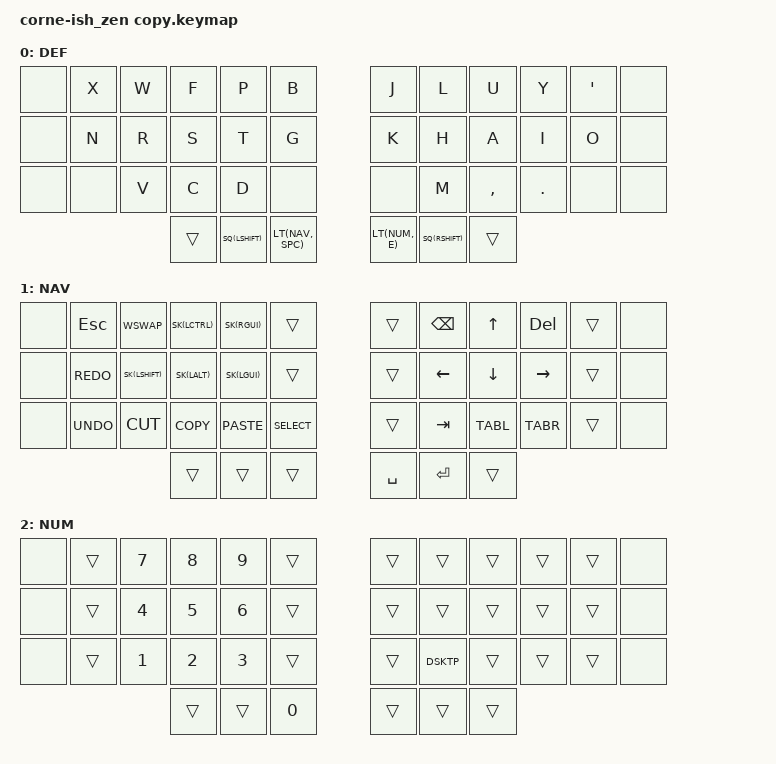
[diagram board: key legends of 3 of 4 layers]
#include <behaviors.dtsi>
#include <dt-bindings/zmk/keys.h>
#include <dt-bindings/zmk/bt.h>

// Keep sticky keys active for a long time so they effectively do not time out
#define STICKY_KEY_TIMEOUT 60000

#define XXXXX &none
#define _____ &trans

#define DEF 0
#define NAV 1
#define NUM 2

#define SK(KEY) &nk KEY KEY
#define MR(LAYER) &mr LAYER 0
#define SQ(KEY) &skq KEY
#define LT(LAYER, KEY) &lt LAYER KEY

#define WSWAP LG(NON_US_BACKSLASH)
#define win_next LS(LG(NON_US_BACKSLASH))
#define TABL LS(LG(LEFT_BRACKET))
#define TABR LS(LG(RIGHT_BRACKET))

#define UNDO LG(Z)
#define REDO LS(LG(Z))
#define COPY LG(C)
#define PASTE LG(V)
#define CUT LG(X)
#define SELECT LG(A)

// #define DSKT1 &kp LS(LC(LA(LG(N1))))
// #define DSKT2 &kp LS(LC(LA(LG(N2))))
// #define DSKT3 &kp LS(LC(LA(LG(N3))))
// #define DSKT4 &kp LS(LC(LA(LG(N4))))
// #define DSKT5 &kp LS(LC(LA(LG(N5))))
// #define DSKT6 &kp LS(LC(LA(LG(N6))))

#define DSKTP SQ(LS(LC(LA(LGUI))))

&kscan0 {
  debounce-period = <14>;
};

&sk {
  release-after-ms = <STICKY_KEY_TIMEOUT>;
};

&caps_word {
  continue-list = <UNDERSCORE MINUS BACKSPACE>;
};

/ {

  behaviors {

    skq: sticky_key_quick_release {
      compatible = "zmk,behavior-sticky-key";
      label = "STICKY_KEY_QUICK_RELEASE";
      #binding-cells = <1>;
      quick-release;
      release-after-ms = <STICKY_KEY_TIMEOUT>;
      bindings = <&kp>;
    };
    
    // Sticky key on tap, normal key on hold
    // Useful for modifier-clicking without the modifier remaining active
    nk: not_so_sticky_key {
      compatible = "zmk,behavior-hold-tap";
      label = "NOT_SO_STICKY_KEY";
      #binding-cells = <2>;
      tapping_term_ms = <200>;
      flavor = "tap-preferred";
      bindings = <&kp>, <&sk>;
    };

    mr: mo_layer_or_repeat {
      compatible = "zmk,behavior-hold-tap";
      label = "MO_REPEAT";
      #binding-cells = <2>;
      flavor = "hold-preferred";
      tapping-term-ms = <200>;
      bindings = <&mo>, <&key_repeat>;
    };
  };

  combos {
    #include "combos.dtsi"
  };


  keymap {
    compatible = "zmk,keymap";

//        // ╭───────┬─────────────┬─────────────┬─────────────┬─────────────┬─────────────╮   ╭─────────────┬─────────────┬─────────────┬─────────────┬─────────────┬───────╮
//             XXXXX   _____         _____         _____         _____         _____             _____         _____         _____         _____         _____         XXXXX
//        // ├───────┼─────────────┼─────────────┼─────────────┼─────────────┼─────────────┤   ├─────────────┼─────────────┼─────────────┼─────────────┼─────────────┼───────┤
//             XXXXX   _____         _____         _____         _____         _____             _____         _____         _____         _____         _____         XXXXX
//        // ├───────┼─────────────┼─────────────┼─────────────┼─────────────┼─────────────┤   ├─────────────┼─────────────┼─────────────┼─────────────┼─────────────┼───────┤
//             XXXXX   _____         _____         _____         _____         _____             _____         _____         _____         _____         _____         XXXXX
//        // ╰───────┴─────────────┴─────────────┴─────────────┼─────────────┼─────────────┤   ├─────────────┼─────────────┼─────────────┴─────────────┴─────────────┴───────╯
//                                                 _____         _____         _____             _____         _____         _____
//        //                                     ╰─────────────┴─────────────┴─────────────╯   ╰─────────────┴─────────────┴─────────────╯


//           SIND
//        // ╭───────┬─────────────┬─────────────┬─────────────┬─────────────┬─────────────╮   ╭─────────────┬─────────────┬─────────────┬─────────────┬─────────────┬───────╮
//             XXXXX   &kp Y         &kp COMMA     &kp H         &kp W         &kp F             &kp Q         &kp K         &kp O         &kp U         &kp X         XXXXX
//        // ├───────┼─────────────┼─────────────┼─────────────┼─────────────┼─────────────┤   ├─────────────┼─────────────┼─────────────┼─────────────┼─────────────┼───────┤
//             XXXXX   &kp S         &kp I         &kp N         &kp D         &kp C             &kp V         &kp T         &kp A         &kp E         &kp R         XXXXX
//        // ├───────┼─────────────┼─────────────┼─────────────┼─────────────┼─────────────┤   ├─────────────┼─────────────┼─────────────┼─────────────┼─────────────┼───────┤
//             XXXXX   &kp J         &kp DOT       &kp L         &kp P         &kp B             &kp G         &kp M         &kp SEMI      &kp SLASH     &kp Z         XXXXX
//        // ╰───────┴─────────────┴─────────────┴─────────────┼─────────────┼─────────────┤   ├─────────────┼─────────────┼─────────────┴─────────────┴─────────────┴───────╯
//                                                 _____         SQ(LSHIFT)    MR(NAV)           LT(NUM, SPC)  SQ(RSHIFT)    _____
//        //                                     ╰─────────────┴─────────────┴─────────────╯   ╰─────────────┴─────────────┴─────────────╯




    base_layer {
      label = "DEF";
//      label = "Aptmak modded";
      bindings = <
        // ╭───────┬─────────────┬─────────────┬─────────────┬─────────────┬─────────────╮   ╭─────────────┬─────────────┬─────────────┬─────────────┬─────────────┬───────╮
             XXXXX   &kp X         &kp W         &kp F         &kp P         &kp B             &kp J         &kp L         &kp U         &kp Y         &kp SQT       XXXXX
        // ├───────┼─────────────┼─────────────┼─────────────┼─────────────┼─────────────┤   ├─────────────┼─────────────┼─────────────┼─────────────┼─────────────┼───────┤
             XXXXX   &kp N         &kp R         &kp S         &kp T         &kp G             &kp K         &kp H         &kp A         &kp I         &kp O         XXXXX
        // ├───────┼─────────────┼─────────────┼─────────────┼─────────────┼─────────────┤   ├─────────────┼─────────────┼─────────────┼─────────────┼─────────────┼───────┤
             XXXXX   XXXXX         &kp V         &kp C         &kp D         XXXXX             XXXXX         &kp M         &kp COMMA     &kp DOT       XXXXX         XXXXX
        // ╰───────┴─────────────┴─────────────┴─────────────┼─────────────┼─────────────┤   ├─────────────┼─────────────┼─────────────┴─────────────┴─────────────┴───────╯
                                                 _____         SQ(LSHIFT)    LT(NAV, SPC)      LT(NUM, E)    SQ(RSHIFT)    _____
        //                                     ╰─────────────┴─────────────┴─────────────╯   ╰─────────────┴─────────────┴─────────────╯
      >;
    };

    nav_layer {
      label = "NAV";
      bindings = <
        // ╭───────┬─────────────┬─────────────┬─────────────┬─────────────┬─────────────╮   ╭─────────────┬─────────────┬─────────────┬─────────────┬─────────────┬───────╮
             XXXXX   &kp ESC       &kp WSWAP     SK(LCTRL)     SK(RGUI)      _____             _____         &kp BSPC      &kp UP        &kp DEL       _____         XXXXX
        // ├───────┼─────────────┼─────────────┼─────────────┼─────────────┼─────────────┤   ├─────────────┼─────────────┼─────────────┼─────────────┼─────────────┼───────┤
             XXXXX   &kp REDO      SK(LSHIFT)    SK(LALT)      SK(LGUI)      _____             _____         &kp LEFT      &kp DOWN      &kp RIGHT     _____         XXXXX
        // ├───────┼─────────────┼─────────────┼─────────────┼─────────────┼─────────────┤   ├─────────────┼─────────────┼─────────────┼─────────────┼─────────────┼───────┤
             XXXXX   &kp UNDO      &kp CUT       &kp COPY      &kp PASTE     &kp SELECT        _____         &kp TAB       &kp TABL      &kp TABR      _____         XXXXX
        // ╰───────┴─────────────┴─────────────┴─────────────┼─────────────┼─────────────┤   ├─────────────┼─────────────┼─────────────┴─────────────┴─────────────┴───────╯
                                                 _____         _____         _____             &kp SPACE     &kp ENTER     _____
        //                                     ╰─────────────┴─────────────┴─────────────╯   ╰─────────────┴─────────────┴─────────────╯
      >;
    };

    num_layer {
      label = "NUM";
      bindings = <
        // ╭───────┬─────────────┬─────────────┬─────────────┬─────────────┬─────────────╮   ╭─────────────┬─────────────┬─────────────┬─────────────┬─────────────┬───────╮
             XXXXX   _____         &kp N7        &kp N8        &kp N9        _____             _____         _____         _____         _____         _____         XXXXX
        // ├───────┼─────────────┼─────────────┼─────────────┼─────────────┼─────────────┤   ├─────────────┼─────────────┼─────────────┼─────────────┼─────────────┼───────┤
             XXXXX   _____         &kp N4        &kp N5        &kp N6        _____             _____         _____         _____         _____         _____         XXXXX
        // ├───────┼─────────────┼─────────────┼─────────────┼─────────────┼─────────────┤   ├─────────────┼─────────────┼─────────────┼─────────────┼─────────────┼───────┤
             XXXXX   _____         &kp N1        &kp N2        &kp N3        _____             _____         DSKTP         _____         _____         _____         XXXXX
        // ╰───────┴─────────────┴─────────────┴─────────────┼─────────────┼─────────────┤   ├─────────────┼─────────────┼─────────────┴─────────────┴─────────────┴───────╯
                                                 _____         _____         &kp N0            _____         _____         _____
        //                                     ╰─────────────┴─────────────┴─────────────╯   ╰─────────────┴─────────────┴─────────────╯
      >;
    };

    blt_layer {
      label = "BLT";
      bindings = <
        // ╭───────┬─────────────┬─────────────┬─────────────┬─────────────┬─────────────╮   ╭─────────────┬─────────────┬─────────────┬─────────────┬─────────────┬───────╮
             XXXXX   _____         _____         _____         _____         _____             &bt BT_SEL 0  &bt BT_SEL 1  &bt BT_SEL 2  &bt BT_SEL 3  &bt BT_SEL 4  XXXXX
        // ├───────┼─────────────┼─────────────┼─────────────┼─────────────┼─────────────┤   ├─────────────┼─────────────┼─────────────┼─────────────┼─────────────┼───────┤
             XXXXX   _____         _____         _____         _____         _____             _____         _____         _____         _____         _____         XXXXX
        // ├───────┼─────────────┼─────────────┼─────────────┼─────────────┼─────────────┤   ├─────────────┼─────────────┼─────────────┼─────────────┼─────────────┼───────┤
             XXXXX   _____         _____         _____         _____         _____             _____         _____         _____         _____         &bt BT_CLR    XXXXX
        // ╰───────┴─────────────┴─────────────┴─────────────┼─────────────┼─────────────┤   ├─────────────┼─────────────┼─────────────┴─────────────┴─────────────┴───────╯
                                                 _____         _____         _____ e            _____         _____         _____
        //                                     ╰─────────────┴─────────────┴─────────────╯   ╰─────────────┴─────────────┴─────────────╯
      >;
    };
  };
};

